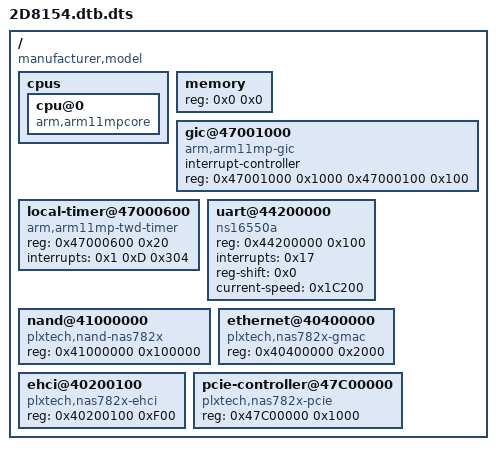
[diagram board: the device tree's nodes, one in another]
/dts-v1/;

/ {
    compatible = "manufacturer,model", "plxtech,nas782x";
    cpus {
        cpu@0 {
            compatible = "arm,arm11mpcore";
        };
    };
    memory {
        device_type = "memory";
        reg = <0x0 0x0>;
    };
    gic@47001000 {
        compatible = "arm,arm11mp-gic";
        interrupt-controller;
        reg = <0x47001000 0x1000 0x47000100 0x100>;
        phandle = <0x1>;
    };
    local-timer@47000600 {
        compatible = "arm,arm11mp-twd-timer";
        reg = <0x47000600 0x20>;
        interrupts = <0x1 0xD 0x304>;
    };
    uart@44200000 {
        compatible = "ns16550a";
        reg = <0x44200000 0x100>;
        interrupts = <0x17>;
        reg-shift = <0x0>;
        current-speed = <0x1C200>;
    };
    nand@41000000 {
        compatible = "plxtech,nand-nas782x";
        reg = <0x41000000 0x100000>;
    };
    ethernet@40400000 {
        compatible = "plxtech,nas782x-gmac";
        reg = <0x40400000 0x2000>;
    };
    ehci@40200100 {
        compatible = "plxtech,nas782x-ehci";
        reg = <0x40200100 0xF00>;
    };
    pcie-controller@47C00000 {
        compatible = "plxtech,nas782x-pcie";
        reg = <0x47C00000 0x1000>;
    };
};
